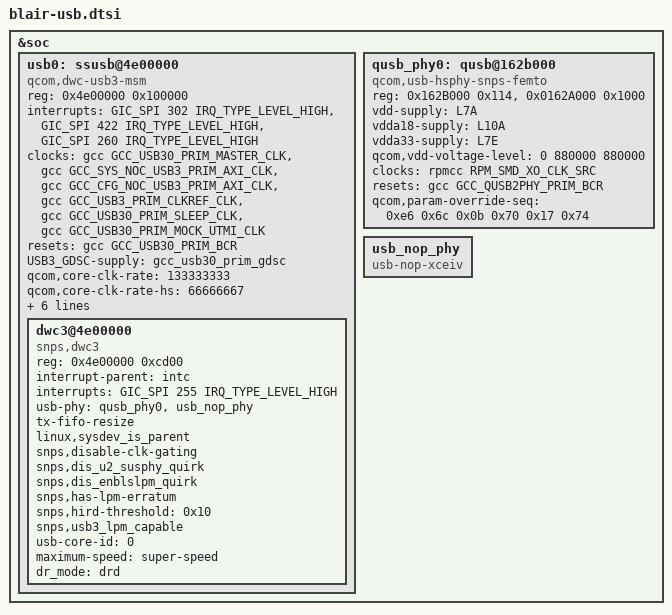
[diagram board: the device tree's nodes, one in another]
#include <dt-bindings/clock/qcom,gcc-blair.h>

&soc {
	/* Primary USB port related controller */
	usb0: ssusb@4e00000 {
		compatible = "qcom,dwc-usb3-msm";
		reg = <0x4e00000 0x100000>;
		reg-names = "core_base";

		#address-cells = <1>;
		#size-cells = <1>;
		ranges;

		interrupts = <GIC_SPI 302 IRQ_TYPE_LEVEL_HIGH>,
			<GIC_SPI 422 IRQ_TYPE_LEVEL_HIGH>,
			<GIC_SPI 260 IRQ_TYPE_LEVEL_HIGH>;
		interrupt-names = "pwr_event_irq", "ss_phy_irq", "hs_phy_irq";

		clocks = <&gcc GCC_USB30_PRIM_MASTER_CLK>,
			<&gcc GCC_SYS_NOC_USB3_PRIM_AXI_CLK>,
			<&gcc GCC_CFG_NOC_USB3_PRIM_AXI_CLK>,
			<&gcc GCC_USB3_PRIM_CLKREF_CLK>,
			<&gcc GCC_USB30_PRIM_SLEEP_CLK>,
			<&gcc GCC_USB30_PRIM_MOCK_UTMI_CLK>;
		clock-names = "core_clk", "iface_clk", "bus_aggr_clk",
				"xo", "sleep_clk", "utmi_clk";

		resets = <&gcc GCC_USB30_PRIM_BCR>;
		reset-names = "core_reset";

		USB3_GDSC-supply = <&gcc_usb30_prim_gdsc>;

		qcom,core-clk-rate = <133333333>;
		qcom,core-clk-rate-hs = <66666667>;
		qcom,num-gsi-evt-buffs = <0x3>;
		qcom,gsi-reg-offset =
			<0x0fc /* GSI_GENERAL_CFG */
			 0x110 /* GSI_DBL_ADDR_L */
			 0x120 /* GSI_DBL_ADDR_H */
			 0x130 /* GSI_RING_BASE_ADDR_L */
			 0x144 /* GSI_RING_BASE_ADDR_H */
			 0x1a4>; /* GSI_IF_STS */
		qcom,dwc-usb3-msm-tx-fifo-size = <21288>;
		qcom,gsi-disable-io-coherency;
		extcon = <&eud>;

		dwc3@4e00000 {
			compatible = "snps,dwc3";
			reg = <0x4e00000 0xcd00>;
			interrupt-parent = <&intc>;
			interrupts = <GIC_SPI 255 IRQ_TYPE_LEVEL_HIGH>;
			usb-phy = <&qusb_phy0>, <&usb_nop_phy>;
			tx-fifo-resize;
			linux,sysdev_is_parent;
			snps,disable-clk-gating;
			snps,dis_u2_susphy_quirk;
			snps,dis_enblslpm_quirk;
			snps,has-lpm-erratum;
			snps,hird-threshold = /bits/ 8 <0x10>;
			snps,usb3_lpm_capable;
			usb-core-id = <0>;
			maximum-speed = "super-speed";
			dr_mode = "drd";
		};
	};

	/* Primary USB port related QUSB2 PHY */
	qusb_phy0: qusb@162b000 {
		compatible = "qcom,usb-hsphy-snps-femto";
		reg = <0x162B000 0x114>,
			<0x0162A000 0x1000>;
		reg-names = "hsusb_phy_base",
			"eud_enable_reg";

		vdd-supply = <&L7A>;
		vdda18-supply = <&L10A>;
		vdda33-supply = <&L7E>;
		qcom,vdd-voltage-level = <0 880000 880000>;

		clocks = <&rpmcc RPM_SMD_XO_CLK_SRC>;
		clock-names = "ref_clk_src";

		resets = <&gcc GCC_QUSB2PHY_PRIM_BCR>;
		reset-names = "phy_reset";
		qcom,param-override-seq =
			<0xe6 0x6c	/* override_x0 */
			 0x0b 0x70	/* override_x1 */
			 0x17 0x74>;	/* override x2 */
	};

	usb_nop_phy: usb_nop_phy {
		compatible = "usb-nop-xceiv";
	};

};

